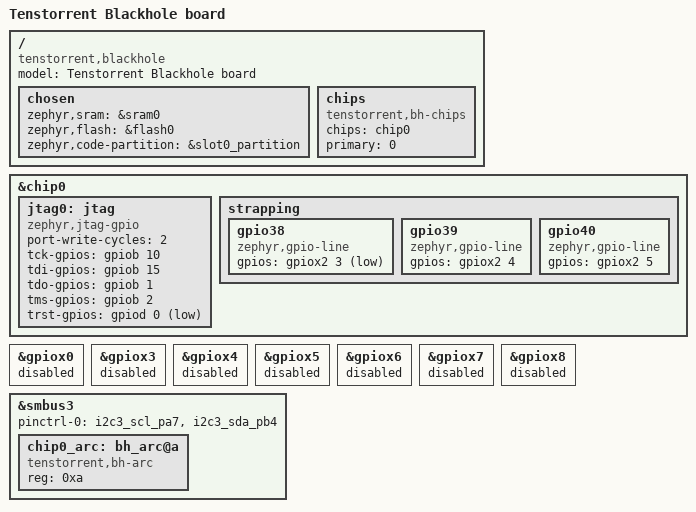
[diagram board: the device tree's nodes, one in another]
/*
 * Copyright (c) 2024 Tenstorrent AI ULC
 *
 * SPDX-License-Identifier: Apache-2.0
 */

/dts-v1/;
#include <st/g0/stm32g0b1Xe.dtsi>
#include <st/g0/stm32g0b1c(b-c-e)tx-pinctrl.dtsi>

/ {
	model = "Tenstorrent Blackhole board";
	compatible = "tenstorrent,blackhole";

	chosen {
		zephyr,sram = &sram0;
		zephyr,flash = &flash0;
		zephyr,code-partition = &slot0_partition;
	};
};

#include "tt_blackhole_dmc.dtsi"

&chip0 {
	jtag0: jtag {
		compatible = "zephyr,jtag-gpio";
		port-write-cycles = <2>;

		tck-gpios = <&gpiob 10 GPIO_ACTIVE_HIGH>;
		tdi-gpios = <&gpiob 15 GPIO_ACTIVE_HIGH>;
		tdo-gpios = <&gpiob 1 GPIO_PULL_UP>;
		tms-gpios = <&gpiob 2 GPIO_ACTIVE_HIGH>;
		trst-gpios = <&gpiod 0 GPIO_ACTIVE_LOW>;
	};

	strapping {
		/* Use QUAD DDR SPI mode, GPIO[39:38] = 2 is QUAD mode, GPIO40 is DDR_EN */
		/* GPIO pin representing strap GPIO38_SPI_MODE_0 */
		gpio38 {
			compatible = "zephyr,gpio-line";
			gpios = <&gpiox2 3 GPIO_ACTIVE_LOW>;
		};

		/* GPIO pin representing strap GPIO39_SPI_MODE_1 */
		gpio39 {
			compatible = "zephyr,gpio-line";
			gpios = <&gpiox2 4 GPIO_ACTIVE_HIGH>;
		};

		/* GPIO pin representing strap GPIO40_SPI_DDR_EN */
		gpio40 {
			compatible = "zephyr,gpio-line";
			gpios = <&gpiox2 5 GPIO_ACTIVE_HIGH>;
		};
	};
};

/ {
	chips {
		compatible = "tenstorrent,bh-chips";
		chips = <&chip0>;
		primary = <0>;
	};
};

&gpiox0 {
	status = "disabled";
};

/*
 * To do- GPIOx3-GPIOx6 should be enabled for QSFP support, but they are not
 * currently detected on a P150a board.
 */
&gpiox3 {
	status = "disabled";
};

&gpiox4 {
	status = "disabled";
};

&gpiox5 {
	status = "disabled";
};

&gpiox6 {
	status = "disabled";
};

&gpiox7 {
	status = "disabled";
};

&gpiox8 {
	status = "disabled";
};

&smbus3 {
	status = "okay";
	pinctrl-0 = <&i2c3_scl_pa7 &i2c3_sda_pb4>;
	pinctrl-names = "default";

	chip0_arc: bh_arc@a {
		compatible = "tenstorrent,bh-arc";
		reg = <0xa>;
	};
};
